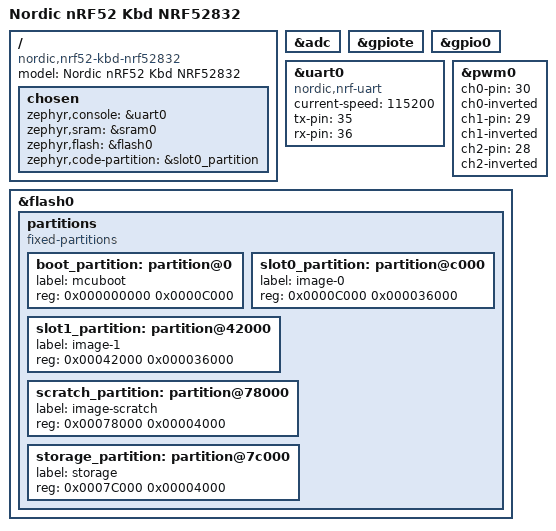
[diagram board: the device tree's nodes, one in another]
/*
 * Copyright (c) 2019 Nordic Semiconductor ASA
 *
 * SPDX-License-Identifier: LicenseRef-BSD-5-Clause-Nordic
 */

/dts-v1/;
#include <nordic/nrf52832_qfaa.dtsi>

/ {
	model = "Nordic nRF52 Kbd NRF52832";
	compatible = "nordic,nrf52-kbd-nrf52832";

	chosen {
		zephyr,console = &uart0;
		zephyr,sram = &sram0;
		zephyr,flash = &flash0;
		zephyr,code-partition = &slot0_partition;
	};
};

&adc {
	status = "okay";
};

&gpiote {
	status = "okay";
};

&gpio0 {
	status = "okay";
};

&uart0 {
	status = "okay";
	compatible = "nordic,nrf-uart";
	current-speed = <115200>;
	tx-pin = <35>;
	rx-pin = <36>;
};

&pwm0 {
	status = "okay";
	ch0-pin = <30>;
	ch0-inverted;
	ch1-pin = <29>;
	ch1-inverted;
	ch2-pin = <28>;
	ch2-inverted;
};

&flash0 {
	/*
	 * For more information, see:
	 * http://docs.zephyrproject.org/devices/dts/flash_partitions.html
	 */
	partitions {
		compatible = "fixed-partitions";
		#address-cells = <1>;
		#size-cells = <1>;

		boot_partition: partition@0 {
			label = "mcuboot";
			reg = <0x000000000 0x0000C000>;
		};
		slot0_partition: partition@c000 {
			label = "image-0";
			reg = <0x0000C000 0x000036000>;
		};
		slot1_partition: partition@42000 {
			label = "image-1";
			reg = <0x00042000 0x000036000>;
		};
		scratch_partition: partition@78000 {
			label = "image-scratch";
			reg = <0x00078000 0x00004000>;
		};
		storage_partition: partition@7c000 {
			label = "storage";
			reg = <0x0007C000 0x00004000>;
		};
	};
};
